# RL7005_IP_SVD register map
Vendor: Realtek
Registers are 32-bit, read-write, reset 0x0 unless marked. A register's access mark holds for its fields unless they carry their own. Offsets are from the block's base; [hi:lo] are bit positions.

## WLAFE_REG
Base 0x4080A480
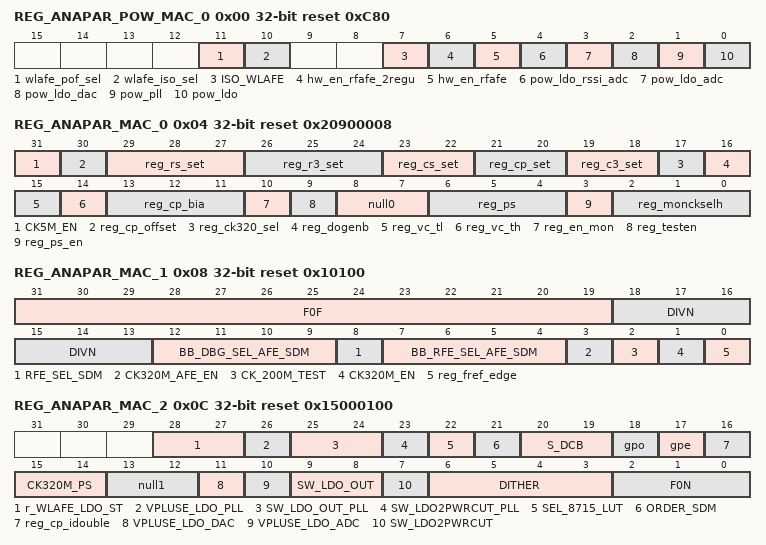
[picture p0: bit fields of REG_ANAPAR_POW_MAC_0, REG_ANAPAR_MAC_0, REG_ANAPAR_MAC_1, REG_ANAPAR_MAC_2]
0x00 REG_ANAPAR_POW_MAC_0 reset 0xC80
  [11] wlafe_pof_sel — Option to power off WLAFE 1: enable ,power off wlafe when bt&wl request off 0: disable ,keep wlafe power on when bt&wl request off
  [10] wlafe_iso_sel — Option to enable isolation of wlafe when power off WLAFE 1: enable ,0x00[7]will be written 1 when wlafe power off 0: disable ,0x00[7]will keep 0 when wlafe power off
  [7] ISO_WLAFE — isolation signal
  [6] hw_en_rfafe_2regu — control 3.3V power reset of wl rfafe, need level shift to 3.3V by regu
  [5] hw_en_rfafe — core power reset of wl rfafe
  [4] pow_ldo_rssi_adc — Power on ldo for rssi adc
  [3] pow_ldo_adc — Power on ldo for adc
  [2] pow_ldo_dac — Power on ldo for dac
  [1] pow_pll — Power on pll
  [0] pow_ldo — Power on AFE power cut and pll ldo
0x04 REG_ANAPAR_MAC_0 reset 0x20900008
  [31] CK5M_EN — 1: Enable 0: Output "1"
  [30] reg_cp_offset — CP current offset 1: on 0:off
  [29:27] reg_rs_set — Set LPF rs 000~111: 1k/3k/5k/7k/9k/11k/13k/15k
  [26:24] reg_r3_set — Set LPF r3 000~111: 1k/3k/5k/7k/9k/11k/13k/15k
  [23:22] reg_cs_set — Set LPF cs 00/01/10/11: 12pF/20pF/24pF/32pF
  [21:20] reg_cp_set — Set LPF cp 00/01/10/11: 0.8pF/1.2pF/1.6pF/2.0pF
  [19:18] reg_c3_set — Set LPF c3 00/01/10/11: 0.4pF/0.8pF/1.2pF/1.6pF
  [17] reg_ck320_sel — Ck 320MHz selection, 1 from ck_ext
  [16] reg_dogenb — enable watch dog 0: Enable 1: Disable
  [15] reg_vc_tl — Tie vc to 1/4 VDD
  [14] reg_vc_th — Tie vc to 3/4 VDD
  [13:11] reg_cp_bia — pll: CP: current: selection: (efuse) 000: 5uA 001: 10uA 010: 15uA 011: 20uA 100: 25uA 101: 30uA 110: 35uA 111: 40uA
  [10] reg_en_mon — 1: Enable 0: Output "1"
  [9] reg_testen — 1: Enable ck_test
  [8:7] null0
  [6:4] reg_ps — Phase swallow setting
  [3] reg_ps_en — Phase swallow enable
  [2:0] reg_monckselh — ck_mon selection 111: 160MHz 001: 110MHz 010: 101MHz 100: 320MHz 011: ck_200M_test 010: ck_sync 001: 5MHz (duty50-50) 000: ck_test
0x08 REG_ANAPAR_MAC_1 reset 0x10100
  [31:19] F0F — SDM divider sel
  [18:13] DIVN — SDM divider sel
  [12:9] BB_DBG_SEL_AFE_SDM — SDM debug selection
  [8] RFE_SEL_SDM — pll referemce clk select 1:table 0:regesters
  [7:4] BB_RFE_SEL_AFE_SDM — pll referemce clk select AFE[0 1 2 3 4 5 6 7 8 9 10 11 12 13 14 15] = [40M 25M 54M 19.2M 20M 26M 38.4M 17.664M 16M 32M 60M 52M 48M 27M 24M 80M] (efuse)
  [3] CK320M_AFE_EN — 1: Enable 0: Output "1"
  [2] CK_200M_TEST
  [1] CK320M_EN — 1: Enable 0: Output "1"
  [0] reg_fref_edge — PLL referemce clk edge select 0: positive 1: negtive
0x0C REG_ANAPAR_MAC_2 reset 0x15000100
  [28:27] r_WLAFE_LDO_ST — stable time select for WLAFE LDO 2'b00:10us, 2'b01:20us, 2'b10:100us, 2'b11:200us
  [26] VPLUSE_LDO_PLL — For PLL(WL PLL LDO)
  [25:24] SW_LDO_OUT_PLL — Ldo voltage 00/01/10/11 0.85/0.9/0.95/1V(PLL LDO)
  [23] SW_LDO2PWRCUT_PLL — 1 power cut mode 0 ldo mode(PLL LDO)
  [22] SEL_8715_LUT — 1 -> 8 phase 500MHz 0 -> 6 phase 640MHz
  [21] ORDER_SDM — SDM order 1: 3th order 0: 2nd order
  [20:19] S_DCB — Driving control buffer 11:larger current
  [18] gpo
  [17] gpe — gpe=1 and gpo=1=>output gpe=1 and gpo=0=>input
  [16] reg_cp_idouble — 1 for cp currnet double
  [15:14] CK320M_PS — Debug
  [13:12] null1
  [11] VPLUSE_LDO_DAC — For DAC(WL DAC LDO)
  [10] VPLUSE_LDO_ADC — For ADC(WL ADC LDO and RSSI ADC LDO)
  [9:8] SW_LDO_OUT — Ldo voltage 00/01/10/11: 0.85V/0.9V/0.95V/1V (ADDA LDO)
  [7] SW_LDO2PWRCUT — 1 power cut mode 0 ldo mode (ADDA LDO)
  [6:3] DITHER — Dither funtion
  [2:0] F0N — SDM divider sel
0x10 REG_DBG_WLAFE_PMC ro
  [31:0] dbg_wlafe_pmc — debug signal of wlafe_pmc
0x14 REG_DBG_WLAFE ro
  [15:0] dbg_wlafe_reg — debug signal of wlafe_reg
0x18 REG_DUMMY
  [31:0] dummy — HW used only , these are for reserved.
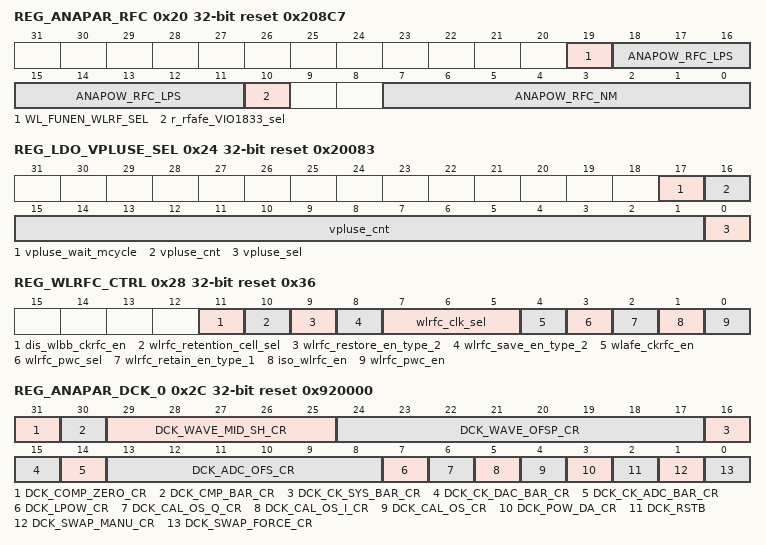
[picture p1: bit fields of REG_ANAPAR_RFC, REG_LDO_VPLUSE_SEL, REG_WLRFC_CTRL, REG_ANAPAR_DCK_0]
0x20 REG_ANAPAR_RFC reset 0x208C7
  [19] WL_FUNEN_WLRF_SEL — 1: select ANAPOW_RFC_NM as ANAPAR_RFC[7:0],used when RFAFE is active 0: select ANAPOW_RFC_LPS as ANAPAR_RFC[7:0],,used when RFAFE is power off
  [18:11] ANAPOW_RFC_LPS — wlan power rf control
  [10] r_rfafe_VIO1833_sel — IND_VIO1833 output decided by: 1: 1.8V 0: 3.3V
  [7:0] ANAPOW_RFC_NM — wlan power rf control
0x24 REG_LDO_VPLUSE_SEL reset 0x20083
  [17] vpluse_wait_mcycle — 1: vpluse_ldo_dac and vpluse_ldo_adc pull low should wait more cycle after ldo pull high
  [16:1] vpluse_cnt — vpluse_ldo high output delay cycle after pll_ldo set high,default:5(1.25us)
  [0] vpluse_sel — vpluse_ldo output decided by: 1: power on ldo 0: ctrl reg
0x28 REG_WLRFC_CTRL access per field reset 0x36
  [11] dis_wlbb_ckrfc_en rw — the gating control of rfc clk is pta_ckrfc_en|wlbb_ckrfc_en|wlafe_ckrfc_en,and wlbb_ckrfc_en can not be control by register directly in RL6678,add option for top to control wlbb_ckrfc_en 1: disable wlbb_ckrfc_en; 0: enable wlbb_ckrfc_en
  [10] wlrfc_retention_cell_sel rw — 1:choose retention cell type I(U22 ULP),which is controlled by 0x28[2] 0:choose retention cell type II(RTKM),which is controlled by 0x28[9:8]
  [9] wlrfc_restore_en_type_2 wo — enable restoring value of retention DFF when wlmac power on,should be assert when reset is high
  [8] wlrfc_save_en_type_2 wo — enable saving value of retention DFF when wlmac power off or pg,should be assert when reset is high
  [7:5] wlrfc_clk_sel rw — rfc clock divider, it is based on 320m wlpll 0: div1 1: div2 2: div3 3/other: divider by this value + 1,(default is 3:80M)
  [4] wlafe_ckrfc_en rw — 1: enable WLRFC clock; 0: gated
  [3] wlrfc_pwc_sel rw — Option to turn off wlrfc pwr cut 1: enable 0: disable RL6973: RFC without retention FF. default is 0
  [2] wlrfc_retain_en_type_1 rw — 1 to 0:gen req to restore register in power on flow 0 to 1:gen req to backup register in power on flow default should be 1,otherwise there be unexpected leakage power when VCC is power off and VCCG is still on
  [1] iso_wlrfc_en rw — Isolation control for wlan rfc 1: isolation 0: attach
  [0] wlrfc_pwc_en rw — 1: gen request of wlan rfc power cut 0: gen request of turn off wlan rfc power cut
0x2C REG_ANAPAR_DCK_0 reset 0x920000
  [31] DCK_COMP_ZERO_CR — 0: DOS [+/-] 1: DOS[+/0/-]
  [30] DCK_CMP_BAR_CR — 0:AVG_VOS1 - AVG_VOS2 / 1:AVG_VOS2 - AVG_VOS1
  [29:25] DCK_WAVE_MID_SH_CR — DA[8:0] to shift -15 ~ +15 the middle value
  [24:17] DCK_WAVE_OFSP_CR — id[7:0] or qd[7:0] = wave_mid_val + wave_ofs_val
  [16] DCK_CK_SYS_BAR_CR — 0: original clock 1: inverse clock
  [15] DCK_CK_DAC_BAR_CR — 0: original clock 1: inverse clock
  [14] DCK_CK_ADC_BAR_CR — 0: original clock 1: inverse clock
  [13:8] DCK_ADC_OFS_CR — Compensate ADC offset : adc2cal_AD[9:0] + ADC_ofs_CR[5:0]
  [7] DCK_LPOW_CR — Low power enable when calibration done
  [6] DCK_CAL_OS_Q_CR — DC-offset calibration enable qpath
  [5] DCK_CAL_OS_I_CR — DC-offset calibration enable ipath
  [4] DCK_CAL_OS_CR — DC-offset calibration enable, ipath and qpath
  [3] DCK_POW_DA_CR — power on for DC-offset calibration
  [2] DCK_RSTB — DCK power on reset
  [1] DCK_SWAP_MANU_CR — SWAP by manual
  [0] DCK_SWAP_FORCE_CR — Force the SWAP from SWAP_Manu_CR
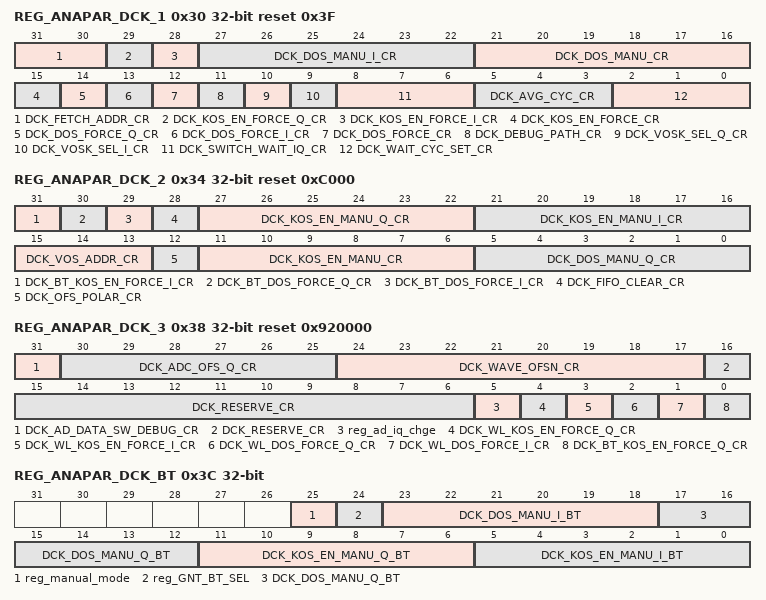
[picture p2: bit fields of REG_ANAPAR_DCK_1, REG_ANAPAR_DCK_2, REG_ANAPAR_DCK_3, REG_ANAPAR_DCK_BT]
0x30 REG_ANAPAR_DCK_1 reset 0x3F
  [31:30] DCK_FETCH_ADDR_CR — Fetch the _AD-DATA 0: first 1: half-odd 2: half-even 3: final
  [29] DCK_KOS_EN_FORCE_Q_CR — Force the KOS_EN_Q[5:0] from KOS_EN_Manu_Q_CR[5:0]
  [28] DCK_KOS_EN_FORCE_I_CR — Force the KOS_EN_I[5:0] from KOS_EN_Manu_I_CR[5:0]
  [27:22] DCK_DOS_MANU_I_CR — DOS_I[5:0] by manual
  [21:16] DCK_DOS_MANU_CR — DOS[5:0] by manual
  [15] DCK_KOS_EN_FORCE_CR — Force the KOS_EN[5:0] from KOS_EN_Manu_CR[5:0]
  [14] DCK_DOS_FORCE_Q_CR — Force the DOS_Q[5:0] from DOS_Manu_Q_CR[5:0]
  [13] DCK_DOS_FORCE_I_CR — Force the DOS_I[5:0] from DOS_Manu_I_CR[5:0]
  [12] DCK_DOS_FORCE_CR — Force the DOS[5:0] from DOS_Manu_CR[5:0]
  [11] DCK_DEBUG_PATH_CR — 1: DCK ready for debug
  [10] DCK_VOSK_SEL_Q_CR — 0: fetch the middle VOS_SR=VOS1-VOS2 0: first / 1: final
  [9] DCK_VOSK_SEL_I_CR — 0: fetch the middle VOS_SR=VOS1-VOS2 0: first / 1: final
  [8:6] DCK_SWITCH_WAIT_IQ_CR — Switch I2Q waiting time
  [5:3] DCK_AVG_CYC_CR — DC-offset calibration fetch ADC data numbers to average
  [2:0] DCK_WAIT_CYC_SET_CR — DC-offset calibration digital waiting clock cycle for setting time
0x34 REG_ANAPAR_DCK_2 reset 0xC000
  [31] DCK_BT_KOS_EN_FORCE_I_CR — Manual write KOSEN at BT mode
  [30] DCK_BT_DOS_FORCE_Q_CR — Manual write DOS data at BT mode
  [29] DCK_BT_DOS_FORCE_I_CR — Manual write DOS data at BT mode
  [28] DCK_FIFO_CLEAR_CR — Clear all FIFO
  [27:22] DCK_KOS_EN_MANU_Q_CR — KOS_EN_Q[5:0] by manual
  [21:16] DCK_KOS_EN_MANU_I_CR — KOS_EN_I[5:0] by manual
  [15:13] DCK_VOS_ADDR_CR — Fetch the k-th offset average value to monitor
  [12] DCK_OFS_POLAR_CR — id[8:0] & qd[8:0] offset +/- => 0(+) / 1(-)
  [11:6] DCK_KOS_EN_MANU_CR — KOS_EN[5:0] by manual
  [5:0] DCK_DOS_MANU_Q_CR — DOS_Q[5:0] by manual
0x38 REG_ANAPAR_DCK_3 reset 0x920000
  [31] DCK_AD_DATA_SW_DEBUG_CR — 0: choose I path vos data 1: choose Q path vos data
  [30:25] DCK_ADC_OFS_Q_CR — Compensate ADC qpath offset: adc2cal_AD[9:0] + ADC_ofs_CR[5:0]
  [24:17] DCK_WAVE_OFSN_CR
  [16:6] DCK_RESERVE_CR
  [5] reg_ad_iq_chge — 0:adci to DCK I ;adcq to DCK Q /1:adci to DCK Q;adcq to DCK I
  [4] DCK_WL_KOS_EN_FORCE_Q_CR — Manual write KOSEN at WL mode
  [3] DCK_WL_KOS_EN_FORCE_I_CR — Manual write KOSEN at WL mode
  [2] DCK_WL_DOS_FORCE_Q_CR — Manual write DOS data at WL mode
  [1] DCK_WL_DOS_FORCE_I_CR — Manual write DOS data at WL mode
  [0] DCK_BT_KOS_EN_FORCE_Q_CR — Manual write KOSEN at BT mode
0x3C REG_ANAPAR_DCK_BT
  [25] reg_manual_mode — 0:select wifi DCK data 1:select bt DCK data
  [24] reg_GNT_BT_SEL — 0:select BTG_GNT_BT_RF to select DCK data 1:select reg_manual_mode to select DCK data
  [23:18] DCK_DOS_MANU_I_BT — DOS_I[5:0] by manual
  [17:12] DCK_DOS_MANU_Q_BT — DOS_Q[5:0] by manual
  [11:6] DCK_KOS_EN_MANU_Q_BT — KOS_EN_Q[5:0] by manual
  [5:0] DCK_KOS_EN_MANU_I_BT — KOS_EN_I[5:0] by manual
